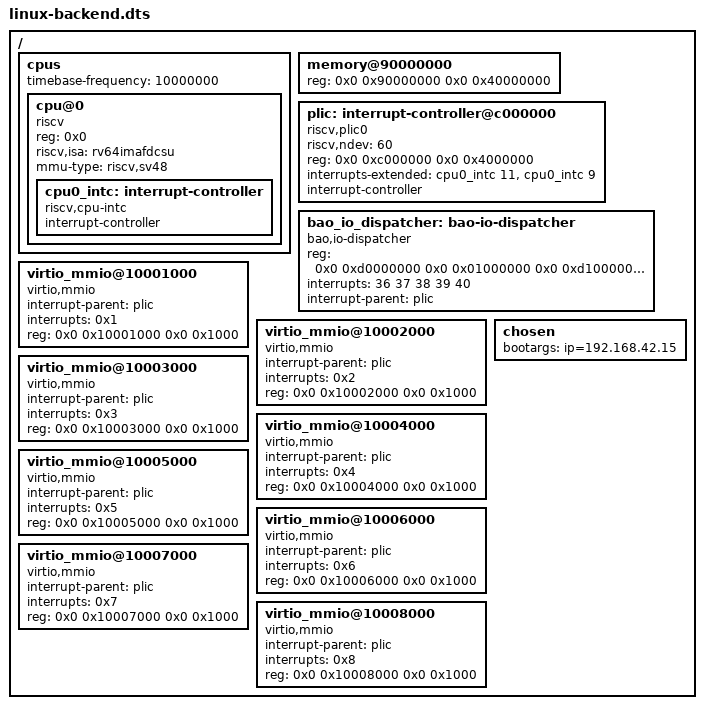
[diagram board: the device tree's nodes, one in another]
/dts-v1/;

/ {
	#address-cells = <0x2>;
	#size-cells = <0x2>;

	cpus {
		#address-cells = <0x1>;
		#size-cells = <0x0>;
		timebase-frequency = <10000000>;

		cpu@0 {
			device_type = "cpu";
			reg = <0x0>;
			status = "okay";
			compatible = "riscv";
			riscv,isa = "rv64imafdcsu";
			mmu-type = "riscv,sv48";

			cpu0_intc: interrupt-controller {
				#interrupt-cells = <0x1>;
				interrupt-controller;
				compatible = "riscv,cpu-intc";
			};
		};
	};

	memory@90000000 {
		device_type = "memory";
		reg = <0x0 0x90000000 0x0 0x40000000>;
	};

	plic: interrupt-controller@c000000 {
		riscv,ndev = <60>;
		reg = <0x0 0xc000000 0x0 0x4000000>;
		interrupts-extended = <
			&cpu0_intc 11 &cpu0_intc 9 
		>;
		interrupt-controller;
		compatible = "riscv,plic0";
		#interrupt-cells = <0x1>;
	};

	bao_io_dispatcher: bao-io-dispatcher {
		compatible = "bao,io-dispatcher";
		reg = <0x0 0xd0000000 0x0 0x01000000
               0x0 0xd1000000 0x0 0x01000000
               0x0 0xd2000000 0x0 0x01000000
               0x0 0xd3000000 0x0 0x01000000
               0x0 0xd4000000 0x0 0x01000000>;
		interrupts = <36 37 38 39 40>;
		interrupt-parent = <&plic>;
	};

	virtio_mmio@10001000 {
		interrupt-parent = <&plic>;
		interrupts = <0x1>;
		reg = <0x0 0x10001000 0x0 0x1000>;
		compatible = "virtio,mmio";
	};

	virtio_mmio@10002000 {
		interrupt-parent = <&plic>;
		interrupts = <0x2>;
		reg = <0x0 0x10002000 0x0 0x1000>;
		compatible = "virtio,mmio";
	};

	virtio_mmio@10003000 {
		interrupt-parent = <&plic>;
		interrupts = <0x3>;
		reg = <0x0 0x10003000 0x0 0x1000>;
		compatible = "virtio,mmio";
	};

	virtio_mmio@10004000 {
		interrupt-parent = <&plic>;
		interrupts = <0x4>;
		reg = <0x0 0x10004000 0x0 0x1000>;
		compatible = "virtio,mmio";
	};
	
	virtio_mmio@10005000 {
		interrupt-parent = <&plic>;
		interrupts = <0x5>;
		reg = <0x0 0x10005000 0x0 0x1000>;
		compatible = "virtio,mmio";
	};

	virtio_mmio@10006000 {
		interrupt-parent = <&plic>;
		interrupts = <0x6>;
		reg = <0x0 0x10006000 0x0 0x1000>;
		compatible = "virtio,mmio";
	};

	virtio_mmio@10007000 {
		interrupt-parent = <&plic>;
		interrupts = <0x7>;
		reg = <0x0 0x10007000 0x0 0x1000>;
		compatible = "virtio,mmio";
	};

	virtio_mmio@10008000 {
		interrupt-parent = <&plic>;
		interrupts = <0x8>;
		reg = <0x0 0x10008000 0x0 0x1000>;
		compatible = "virtio,mmio";
	};

	chosen {
		bootargs = "ip=192.168.42.15";
	};
};
